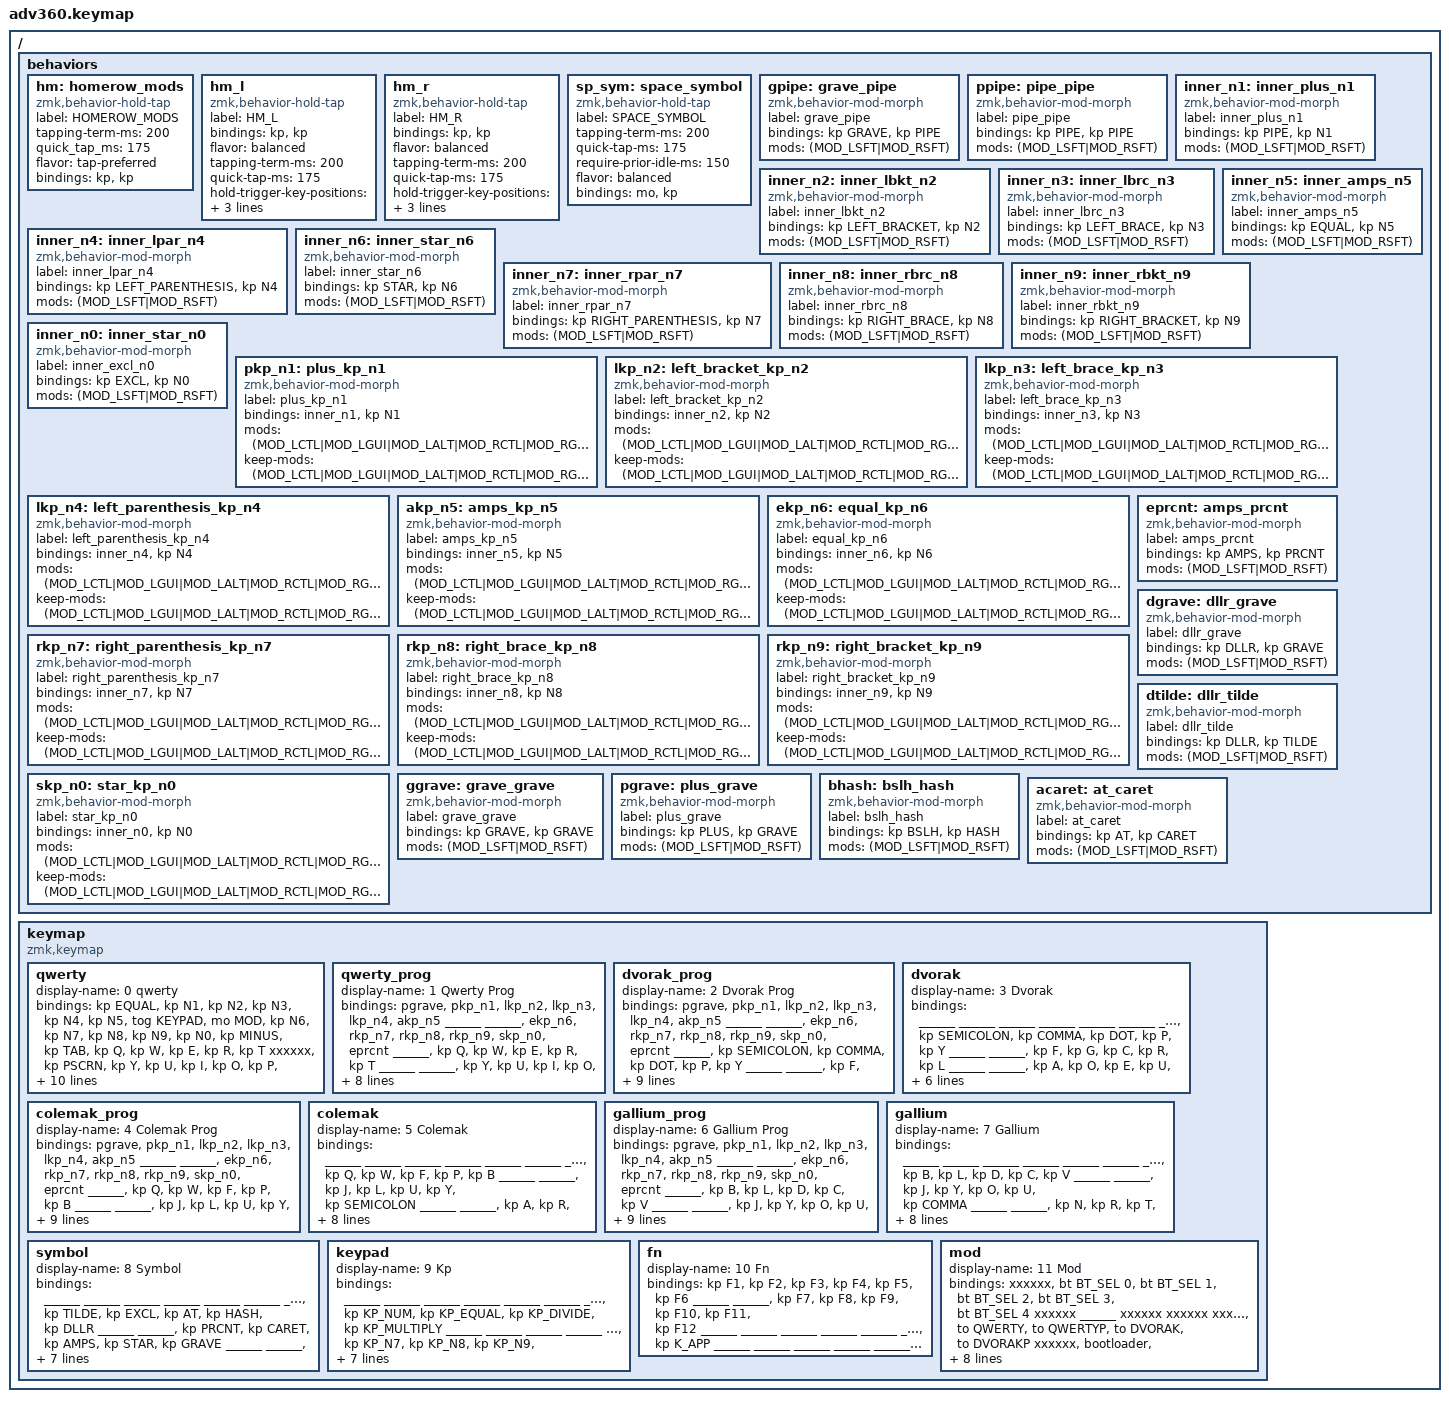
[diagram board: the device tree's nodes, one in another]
#include <dt-bindings/zmk/stp.h>
#include <behaviors.dtsi>
#include <dt-bindings/zmk/backlight.h>
#include <dt-bindings/zmk/bt.h>
#include <dt-bindings/zmk/keys.h>
#include <dt-bindings/zmk/rgb.h>

#define ______ &trans
#define xxxxxx &none

#define QWERTY 0
#define QWERTYP 1
#define DVORAKP 2
#define DVORAK 3
#define COLEMAKP 4
#define COLEMAK 5
#define GALLIUMP 6
#define GALLIUM 7
#define SYMBOL 8
#define KEYPAD 9
#define FN 10
#define MOD 11

/ {
    behaviors {
        #include "macros.dtsi"
        #include "version.dtsi"

        hm: homerow_mods {
            compatible = "zmk,behavior-hold-tap";
            label = "HOMEROW_MODS";
            #binding-cells = <2>;
            tapping-term-ms = <200>;
            quick_tap_ms = <175>;
            flavor = "tap-preferred";
            bindings = <&kp>, <&kp>;
        };

        hm_l: hm_l {
            compatible = "zmk,behavior-hold-tap";
            label = "HM_L";
            bindings = <&kp>, <&kp>;

            #binding-cells = <2>;
            flavor = "balanced";
            tapping-term-ms = <200>;
            quick-tap-ms = <175>;
            hold-trigger-key-positions = <66 35 36 52 67 65 7 8 9 10 11 12 13 21 22 23 24 25 26 27 38 39 40 41 42 43 44 45 54 55 56 57 58 59 70 71 72 73 74 75 37 53 69 68>;
            hold-trigger-on-release;
            global-quick-tap;
        };

        hm_r: hm_r {
            compatible = "zmk,behavior-hold-tap";
            label = "HM_R";
            bindings = <&kp>, <&kp>;

            #binding-cells = <2>;
            flavor = "balanced";
            tapping-term-ms = <200>;
            quick-tap-ms = <175>;
            hold-trigger-key-positions = <0 1 2 3 4 5 6 14 15 16 17 18 19 20 28 29 30 31 32 33 34 35 36 46 47 48 49 50 51 52 60 61 62 63 64 65 66 67 37 38 53 68 69 70>;
            hold-trigger-on-release;
            global-quick-tap;
        };

        sp_sym: space_symbol {
            compatible = "zmk,behavior-hold-tap";
            label = "SPACE_SYMBOL";
            #binding-cells = <2>;
            tapping-term-ms = <200>;
            quick-tap-ms = <175>;
            require-prior-idle-ms = <150>;
            flavor = "balanced";
            bindings = <&mo>, <&kp>;
        };

        gpipe: grave_pipe {
            compatible = "zmk,behavior-mod-morph";
            label = "grave_pipe";
            #binding-cells = <0>;
            bindings = <&kp GRAVE>, <&kp PIPE>;
            mods = <(MOD_LSFT|MOD_RSFT)>;
        };

        ppipe: pipe_pipe {
            compatible = "zmk,behavior-mod-morph";
            label = "pipe_pipe";
            #binding-cells = <0>;
            bindings = <&kp PIPE>, <&kp PIPE>;
            mods = <(MOD_LSFT|MOD_RSFT)>;
        };

        /* Inner morphs: shift-only symbol/number swap */
        inner_n1: inner_plus_n1 {
            compatible = "zmk,behavior-mod-morph";
            label = "inner_plus_n1";
            #binding-cells = <0>;
            bindings = <&kp PIPE>, <&kp N1>;
            mods = <(MOD_LSFT|MOD_RSFT)>;
        };
        inner_n2: inner_lbkt_n2 {
            compatible = "zmk,behavior-mod-morph";
            label = "inner_lbkt_n2";
            #binding-cells = <0>;
            bindings = <&kp LEFT_BRACKET>, <&kp N2>;
            mods = <(MOD_LSFT|MOD_RSFT)>;
        };
        inner_n3: inner_lbrc_n3 {
            compatible = "zmk,behavior-mod-morph";
            label = "inner_lbrc_n3";
            #binding-cells = <0>;
            bindings = <&kp LEFT_BRACE>, <&kp N3>;
            mods = <(MOD_LSFT|MOD_RSFT)>;
        };
        inner_n4: inner_lpar_n4 {
            compatible = "zmk,behavior-mod-morph";
            label = "inner_lpar_n4";
            #binding-cells = <0>;
            bindings = <&kp LEFT_PARENTHESIS>, <&kp N4>;
            mods = <(MOD_LSFT|MOD_RSFT)>;
        };
        inner_n5: inner_amps_n5 {
            compatible = "zmk,behavior-mod-morph";
            label = "inner_amps_n5";
            #binding-cells = <0>;
            bindings = <&kp EQUAL>, <&kp N5>;
            mods = <(MOD_LSFT|MOD_RSFT)>;
        };
        inner_n6: inner_star_n6 {
            compatible = "zmk,behavior-mod-morph";
            label = "inner_star_n6";
            #binding-cells = <0>;
            bindings = <&kp STAR>, <&kp N6>;
            mods = <(MOD_LSFT|MOD_RSFT)>;
        };
        inner_n7: inner_rpar_n7 {
            compatible = "zmk,behavior-mod-morph";
            label = "inner_rpar_n7";
            #binding-cells = <0>;
            bindings = <&kp RIGHT_PARENTHESIS>, <&kp N7>;
            mods = <(MOD_LSFT|MOD_RSFT)>;
        };
        inner_n8: inner_rbrc_n8 {
            compatible = "zmk,behavior-mod-morph";
            label = "inner_rbrc_n8";
            #binding-cells = <0>;
            bindings = <&kp RIGHT_BRACE>, <&kp N8>;
            mods = <(MOD_LSFT|MOD_RSFT)>;
        };
        inner_n9: inner_rbkt_n9 {
            compatible = "zmk,behavior-mod-morph";
            label = "inner_rbkt_n9";
            #binding-cells = <0>;
            bindings = <&kp RIGHT_BRACKET>, <&kp N9>;
            mods = <(MOD_LSFT|MOD_RSFT)>;
        };
        inner_n0: inner_star_n0 {
            compatible = "zmk,behavior-mod-morph";
            label = "inner_excl_n0";
            #binding-cells = <0>;
            bindings = <&kp EXCL>, <&kp N0>;
            mods = <(MOD_LSFT|MOD_RSFT)>;
        };

        /* Outer morphs: when ctrl/super/alt held, send number with those mods preserved (shift passes through untouched).
           When no ctrl/super/alt, delegate to inner morph for shift-based symbol/number swap. */
        pkp_n1: plus_kp_n1 {
            compatible = "zmk,behavior-mod-morph";
            label = "plus_kp_n1";
            #binding-cells = <0>;
            bindings = <&inner_n1>, <&kp N1>;
            mods = <(MOD_LCTL|MOD_LGUI|MOD_LALT|MOD_RCTL|MOD_RGUI|MOD_RALT)>;
            keep-mods = <(MOD_LCTL|MOD_LGUI|MOD_LALT|MOD_RCTL|MOD_RGUI|MOD_RALT)>;
        };
        lkp_n2: left_bracket_kp_n2 {
            compatible = "zmk,behavior-mod-morph";
            label = "left_bracket_kp_n2";
            #binding-cells = <0>;
            bindings = <&inner_n2>, <&kp N2>;
            mods = <(MOD_LCTL|MOD_LGUI|MOD_LALT|MOD_RCTL|MOD_RGUI|MOD_RALT)>;
            keep-mods = <(MOD_LCTL|MOD_LGUI|MOD_LALT|MOD_RCTL|MOD_RGUI|MOD_RALT)>;
        };
        lkp_n3: left_brace_kp_n3 {
            compatible = "zmk,behavior-mod-morph";
            label = "left_brace_kp_n3";
            #binding-cells = <0>;
            bindings = <&inner_n3>, <&kp N3>;
            mods = <(MOD_LCTL|MOD_LGUI|MOD_LALT|MOD_RCTL|MOD_RGUI|MOD_RALT)>;
            keep-mods = <(MOD_LCTL|MOD_LGUI|MOD_LALT|MOD_RCTL|MOD_RGUI|MOD_RALT)>;
        };
        lkp_n4: left_parenthesis_kp_n4 {
            compatible = "zmk,behavior-mod-morph";
            label = "left_parenthesis_kp_n4";
            #binding-cells = <0>;
            bindings = <&inner_n4>, <&kp N4>;
            mods = <(MOD_LCTL|MOD_LGUI|MOD_LALT|MOD_RCTL|MOD_RGUI|MOD_RALT)>;
            keep-mods = <(MOD_LCTL|MOD_LGUI|MOD_LALT|MOD_RCTL|MOD_RGUI|MOD_RALT)>;
        };
        akp_n5: amps_kp_n5 {
            compatible = "zmk,behavior-mod-morph";
            label = "amps_kp_n5";
            #binding-cells = <0>;
            bindings = <&inner_n5>, <&kp N5>;
            mods = <(MOD_LCTL|MOD_LGUI|MOD_LALT|MOD_RCTL|MOD_RGUI|MOD_RALT)>;
            keep-mods = <(MOD_LCTL|MOD_LGUI|MOD_LALT|MOD_RCTL|MOD_RGUI|MOD_RALT)>;
        };
        ekp_n6: equal_kp_n6 {
            compatible = "zmk,behavior-mod-morph";
            label = "equal_kp_n6";
            #binding-cells = <0>;
            bindings = <&inner_n6>, <&kp N6>;
            mods = <(MOD_LCTL|MOD_LGUI|MOD_LALT|MOD_RCTL|MOD_RGUI|MOD_RALT)>;
            keep-mods = <(MOD_LCTL|MOD_LGUI|MOD_LALT|MOD_RCTL|MOD_RGUI|MOD_RALT)>;
        };
        rkp_n7: right_parenthesis_kp_n7 {
            compatible = "zmk,behavior-mod-morph";
            label = "right_parenthesis_kp_n7";
            #binding-cells = <0>;
            bindings = <&inner_n7>, <&kp N7>;
            mods = <(MOD_LCTL|MOD_LGUI|MOD_LALT|MOD_RCTL|MOD_RGUI|MOD_RALT)>;
            keep-mods = <(MOD_LCTL|MOD_LGUI|MOD_LALT|MOD_RCTL|MOD_RGUI|MOD_RALT)>;
        };
        rkp_n8: right_brace_kp_n8 {
            compatible = "zmk,behavior-mod-morph";
            label = "right_brace_kp_n8";
            #binding-cells = <0>;
            bindings = <&inner_n8>, <&kp N8>;
            mods = <(MOD_LCTL|MOD_LGUI|MOD_LALT|MOD_RCTL|MOD_RGUI|MOD_RALT)>;
            keep-mods = <(MOD_LCTL|MOD_LGUI|MOD_LALT|MOD_RCTL|MOD_RGUI|MOD_RALT)>;
        };
        rkp_n9: right_bracket_kp_n9 {
            compatible = "zmk,behavior-mod-morph";
            label = "right_bracket_kp_n9";
            #binding-cells = <0>;
            bindings = <&inner_n9>, <&kp N9>;
            mods = <(MOD_LCTL|MOD_LGUI|MOD_LALT|MOD_RCTL|MOD_RGUI|MOD_RALT)>;
            keep-mods = <(MOD_LCTL|MOD_LGUI|MOD_LALT|MOD_RCTL|MOD_RGUI|MOD_RALT)>;
        };
        skp_n0: star_kp_n0 {
            compatible = "zmk,behavior-mod-morph";
            label = "star_kp_n0";
            #binding-cells = <0>;
            bindings = <&inner_n0>, <&kp N0>;
            mods = <(MOD_LCTL|MOD_LGUI|MOD_LALT|MOD_RCTL|MOD_RGUI|MOD_RALT)>;
            keep-mods = <(MOD_LCTL|MOD_LGUI|MOD_LALT|MOD_RCTL|MOD_RGUI|MOD_RALT)>;
        };

        eprcnt: amps_prcnt {
            compatible = "zmk,behavior-mod-morph";
            label = "amps_prcnt";
            #binding-cells = <0>;
            bindings = <&kp AMPS>, <&kp PRCNT>;
            mods = <(MOD_LSFT|MOD_RSFT)>;
        };

        dgrave: dllr_grave {
            compatible = "zmk,behavior-mod-morph";
            label = "dllr_grave";
            #binding-cells = <0>;
            bindings = <&kp DLLR>, <&kp GRAVE>;
            mods = <(MOD_LSFT|MOD_RSFT)>;
        };
        dtilde: dllr_tilde {
            compatible = "zmk,behavior-mod-morph";
            label = "dllr_tilde";
            #binding-cells = <0>;
            bindings = <&kp DLLR>, <&kp TILDE>;
            mods = <(MOD_LSFT|MOD_RSFT)>;
        };

        ggrave: grave_grave {
            compatible = "zmk,behavior-mod-morph";
            label = "grave_grave";
            #binding-cells = <0>;
            bindings = <&kp GRAVE>, <&kp GRAVE>;
            mods = <(MOD_LSFT|MOD_RSFT)>;
        };

        pgrave: plus_grave {
            compatible = "zmk,behavior-mod-morph";
            label = "plus_grave";
            #binding-cells = <0>;
            bindings = <&kp PLUS>, <&kp GRAVE>;
            mods = <(MOD_LSFT|MOD_RSFT)>;
        };

        bhash: bslh_hash {
            compatible = "zmk,behavior-mod-morph";
            label = "bslh_hash";
            #binding-cells = <0>;
            bindings = <&kp BSLH>, <&kp HASH>;
            mods = <(MOD_LSFT|MOD_RSFT)>;
        };

        acaret: at_caret {
            compatible = "zmk,behavior-mod-morph";
            label = "at_caret";
            #binding-cells = <0>;
            bindings = <&kp AT>, <&kp CARET>;
            mods = <(MOD_LSFT|MOD_RSFT)>;
        };
    };

    keymap {
        compatible = "zmk,keymap";

        qwerty {
            display-name = "0 qwerty";
            bindings = <
                &kp EQUAL  &kp N1     &kp N2    &kp N3    &kp N4     &kp N5  &tog KEYPAD                                                 &mo MOD    &kp N6  &kp N7    &kp N8     &kp N9    &kp N0    &kp MINUS
                &kp TAB    &kp Q      &kp W     &kp E     &kp R      &kp T   xxxxxx                                                      &kp PSCRN  &kp Y   &kp U     &kp I      &kp O     &kp P     &kp BSLH
                &kp ESC    &kp A      &kp S     &kp D     &kp F      &kp G   xxxxxx       &kp LALT   &kp LGUI      &kp LGUI   &kp RCTRL  &kp INS    &kp H   &kp J     &kp K      &kp L     &kp SEMI  &kp SQT
                &kp LSHFT  &kp Z      &kp X     &kp C     &kp V      &kp B                           &kp HOME      &kp PG_UP                        &kp N   &kp M     &kp COMMA  &kp DOT   &kp FSLH  &kp RSHFT
                &kp LCTRL  &kp GRAVE  &mo FN    &kp LEFT  &kp RIGHT          &kp SPACE    &kp DEL    &kp END       &kp PG_DN  &kp ENTER  &kp BSPC           &kp UP    &kp DOWN   &kp LBKT  &kp RBKT  &mo FN
            >;
        };

        qwerty_prog {
            display-name = "1 Qwerty Prog";
            bindings = <
                &pgrave    &pkp_n1    &lkp_n2  &lkp_n3  &lkp_n4  &akp_n5  ______                                      ______  &ekp_n6  &rkp_n7  &rkp_n8    &rkp_n9  &skp_n0   &eprcnt
                ______     &kp Q      &kp W    &kp E    &kp R    &kp T    ______                                      ______  &kp Y    &kp U    &kp I      &kp O    &kp P     &bhash
                ______     &kp A      &kp S    &kp D    &kp F    &kp G    ______  ______  ______      ______  ______  ______  &kp H    &kp J    &kp K      &kp L    &kp SEMI  &kp MINUS
                ______     &kp Z      &kp X    &kp C    &kp V    &kp B                    ______      ______                  &kp N    &kp M    &kp COMMA  &kp DOT  &kp FSLH  ______
                ______     &dtilde    ______   ______   ______            ______  ______  ______      ______  ______  ______           ______   ______     &kp SQT  &acaret   ______
            >;
        };

        dvorak_prog {
            display-name = "2 Dvorak Prog";
            bindings = <
                &pgrave    &pkp_n1        &lkp_n2    &lkp_n3  &lkp_n4  &akp_n5  ______                                      ______  &ekp_n6  &rkp_n7  &rkp_n8  &rkp_n9  &skp_n0  &eprcnt
                ______     &kp SEMICOLON  &kp COMMA  &kp DOT  &kp P    &kp Y    ______                                      ______  &kp F    &kp G    &kp C    &kp R    &kp L    &kp BSLH
                ______     &kp A          &kp O      &kp E    &kp U    &kp I    ______  ______  ______      ______  ______  ______  &kp D    &kp H    &kp T    &kp N    &kp S    &kp MINUS
                ______     &kp SQT        &kp Q      &kp J    &kp K    &kp X                    ______      ______                  &kp B    &kp M    &kp W    &kp V    &kp Z    ______
                &mo FN     &dtilde        &kp CAPS     ______   ______          ______  ______  ______      ______  ______  ______           ______   ______   &kp SQT  &acaret  ______
            >;
        };

        dvorak {
            display-name = "3 Dvorak";
            bindings = <
                ______     ______         ______     ______   ______   ______  ______                                      ______  ______  ______   ______   ______   ______   ______
                ______     &kp SEMICOLON  &kp COMMA  &kp DOT  &kp P    &kp Y   ______                                      ______  &kp F   &kp G    &kp C    &kp R    &kp L    ______
                ______     &kp A          &kp O      &kp E    &kp U    &kp I   ______      ______  ______  ______  ______  ______  &kp D   &kp H    &kp T    &kp N    &kp S    &kp MINUS
                ______     &kp SQT        &kp Q      &kp J    &kp K    &kp X                       ______  ______                  &kp B   &kp M    &kp W    &kp V    &kp Z    ______
                ______     ______         ______     ______   ______           &sp_sym SYMBOL SPACE  ______  ______  ______  ______  ______          ______   ______   ______   ______   ______
            >;
        };

        colemak_prog {
            display-name = "4 Colemak Prog";
            bindings = <
                &pgrave    &pkp_n1    &lkp_n2  &lkp_n3  &lkp_n4  &akp_n5  ______                                      ______  &ekp_n6  &rkp_n7  &rkp_n8    &rkp_n9     &skp_n0        &eprcnt
                ______     &kp Q      &kp W    &kp F    &kp P    &kp B    ______                                      ______  &kp J    &kp L    &kp U      &kp Y       &kp SEMICOLON  &kp BSLH
                ______     &kp A      &kp R    &kp S    &kp T    &kp G    ______  ______  ______      ______  ______  ______  &kp M    &kp N    &kp E      &kp I       &kp O          &kp MINUS
                ______     &kp Z      &kp X    &kp C    &kp D    &kp V                    ______      ______                  &kp K    &kp H    &kp COMMA  &kp PERIOD  &kp SLASH      ______
                &mo FN     &dtilde    &kp CAPS   ______   ______          ______  ______  ______      ______  ______  ______           ______   ______     &kp SQT     &acaret        ______
            >;
        };

        colemak {
            display-name = "5 Colemak";
            bindings = <
                ______     ______   ______   ______   ______   ______  ______                                      ______  ______  ______   ______     ______      ______         ______
                ______     &kp Q    &kp W    &kp F    &kp P    &kp B   ______                                      ______  &kp J   &kp L    &kp U      &kp Y       &kp SEMICOLON  ______
                ______     &kp A    &kp R    &kp S    &kp T    &kp G   ______      ______  ______  ______  ______  ______  &kp M   &kp N    &kp E      &kp I       &kp O          &kp MINUS
                ______     &kp Z    &kp X    &kp C    &kp D    &kp V                       ______  ______                  &kp K   &kp H    &kp COMMA  &kp PERIOD  &kp SLASH      ______
                ______     ______   ______   ______   ______           &sp_sym SYMBOL SPACE  ______  ______  ______  ______  ______          ______   ______     ______      ______         ______
            >;
        };

        gallium_prog {
            display-name = "6 Gallium Prog";
            bindings = <
                &pgrave    &pkp_n1  &lkp_n2  &lkp_n3  &lkp_n4  &akp_n5  ______                                      ______  &ekp_n6  &rkp_n7  &rkp_n8   &rkp_n9   &skp_n0    &eprcnt
                ______     &kp B    &kp L    &kp D    &kp C    &kp V    ______                                      ______  &kp J    &kp Y    &kp O     &kp U     &kp COMMA  &bhash
                ______     &kp N    &kp R    &kp T    &kp S    &kp G    ______  ______  ______      ______  ______  ______  &kp P    &kp H    &kp A     &kp E     &kp I      &kp MINUS
                ______     &kp X    &kp Q    &kp M    &kp W    &kp Z                    ______      ______                  &kp K    &kp F    &kp SQT   &kp SEMI  &kp DOT    ______
                &mo FN     &dtilde  &kp CAPS ______   ______            ______  ______  ______      ______  ______  ______           ______   ______    &kp FSLH  &acaret    ______
            >;
        };

        gallium {
            display-name = "7 Gallium";
            bindings = <
                ______     ______   ______   ______   ______     ______  ______                                      ______  ______  ______   ______     ______    ______     ______
                ______     &kp B    &kp L    &kp D    &kp C      &kp V   ______                                      ______  &kp J   &kp Y    &kp O      &kp U     &kp COMMA  ______
                ______     &kp N    &kp R    &kp T    &kp S      &kp G   ______      ______  ______  ______  ______  ______  &kp P   &kp H    &kp A      &kp E     &kp I      &kp FSLH
                ______     &kp X    &kp Q    &kp M    &kp W      &kp Z                       ______  ______                  &kp K   &kp F    &kp SQT    &kp SEMI  &kp DOT    ______
                ______     ______   ______   ______   ______              &sp_sym SYMBOL SPACE  ______  ______  ______  ______  ______          ______   ______     ______    ______     ______
            >;
        };

        symbol {
            display-name = "8 Symbol";
            bindings = <
                ______  ______     ______    ______    ______    ______  ______                                      ______  ______    ______     ______     ______    ______    ______
                ______  &kp TILDE  &kp EXCL  &kp AT    &kp HASH  &kp DLLR  ______                                  ______  &kp PRCNT &kp CARET  &kp AMPS   &kp STAR  &kp GRAVE ______
                ______  &kp LBRC   &kp LPAR  &kp RPAR  &kp RBRC  &kp EQUAL ______  ______  ______  ______  ______  ______  &kp PLUS  &kp MINUS  &kp UNDER  &kp BSLH  &kp PIPE  ______
                ______  &kp LT     &kp LBKT  &kp RBKT  &kp GT    &kp QMARK                 ______  ______                  &kp FSLH  &kp SQT    &kp DQT    &kp SEMI  &kp COLON ______
                ______  ______     ______    ______    ______              ______  ______  ______    ______  ______  ______            ______     ______     ______    ______    ______
            >;
        };

        keypad {
            display-name = "9 Kp";
            bindings = <
                ______  ______  ______  ______  ______  ______  ______                                      ______     ______  &kp KP_NUM  &kp KP_EQUAL  &kp KP_DIVIDE  &kp KP_MULTIPLY  ______
                ______  ______  ______  ______  ______  ______  ______                                      ______     ______  &kp KP_N7   &kp KP_N8     &kp KP_N9      &kp KP_MINUS     ______
                ______  ______  ______  ______  ______  ______  ______  ______  ______      ______  ______  ______     ______  &kp KP_N4   &kp KP_N5     &kp KP_N6      &kp KP_PLUS      ______
                ______  ______  ______  ______  ______  ______                  ______      ______                     ______  &kp KP_N1   &kp KP_N2     &kp KP_N3      &kp KP_ENTER     ______
                ______  ______  ______  ______  ______          ______  ______  ______      ______  ______  &kp KP_N0          ______      ______        &kp KP_DOT     ______           ______
            >;
        };

        fn {
            display-name = "10 Fn";
            bindings = <
                &kp F1  &kp F2  &kp F3     &kp F4  &kp F5  &kp F6  ______                                                  ______          &kp F7  &kp F8  &kp F9  &kp F10  &kp F11  &kp F12
                ______  ______  ______     ______  ______  ______  ______                                                   ______          ______  ______  ______  ______   ______   ______
                ______  ______  ______     ______  ______  ______  ______       ______  ______      ______  ______  ______          ______  ______  ______  ______   ______   ______
                ______  ______  ______     ______  ______  ______                       ______      ______                          ______  ______  ______  ______   ______   ______
                ______  ______  &kp K_APP  ______  ______          ______       ______  ______      ______  ______  ______                  ______  ______  ______   ______   ______
            >;
        };

        mod {
            display-name = "11 Mod";
            bindings = <
                xxxxxx          &bt BT_SEL 0  &bt BT_SEL 1  &bt BT_SEL 2  &bt BT_SEL 3  &bt BT_SEL 4  xxxxxx                                                  ______                  xxxxxx  xxxxxx      xxxxxx      xxxxxx  xxxxxx  xxxxxx
                xxxxxx          &to QWERTY    &to QWERTYP   &to DVORAK    &to DVORAKP   xxxxxx        &bootloader                                             &bootloader             xxxxxx  &to COLEMAK &to COLEMAKP &to GALLIUM &to GALLIUMP xxxxxx
                &studio_unlock  xxxxxx        xxxxxx        xxxxxx        xxxxxx        xxxxxx        xxxxxx       xxxxxx  xxxxxx     &bt BT_CLR  xxxxxx      &rgb_ug RGB_MEFS_CMD 5  xxxxxx  xxxxxx      xxxxxx      xxxxxx  xxxxxx  xxxxxx
                xxxxxx          xxxxxx        xxxxxx        xxxxxx        &macro_ver    xxxxxx                             xxxxxx     xxxxxx                                          xxxxxx  xxxxxx      xxxxxx      xxxxxx  xxxxxx  xxxxxx
                xxxxxx          xxxxxx        xxxxxx        xxxxxx        xxxxxx                      xxxxxx       xxxxxx  xxxxxx     xxxxxx      &bl BL_TOG  &rgb_ug RGB_TOG                 &bl BL_INC  &bl BL_DEC  xxxxxx  xxxxxx  xxxxxx
            >;
        };

    };
};
